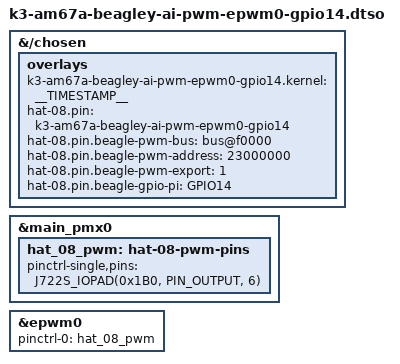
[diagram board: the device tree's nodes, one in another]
// SPDX-License-Identifier: GPL-2.0-only OR MIT
/*
 * DT Overlay for GPIO14 epwm0 connections within the expansion header.
 *
 * Copyright (C) 2023 Texas Instruments Incorporated - https://www.ti.com/
 *
 */

/dts-v1/;
/plugin/;

#include <dt-bindings/gpio/gpio.h>
#include "k3-pinctrl.h"

/*
 * Helper to show loaded overlays under: /proc/device-tree/chosen/overlays/
*/
&{/chosen} {
	overlays {
		k3-am67a-beagley-ai-pwm-epwm0-gpio14.kernel = __TIMESTAMP__;
		hat-08.pin = "k3-am67a-beagley-ai-pwm-epwm0-gpio14";
		hat-08.pin.beagle-pwm-bus = "bus@f0000";
		hat-08.pin.beagle-pwm-address = "23000000";
		hat-08.pin.beagle-pwm-export = "1";
		hat-08.pin.beagle-gpio-pi = "GPIO14";
	};
};

&main_pmx0 {
	hat_08_pwm: hat-08-pwm-pins {
		pinctrl-single,pins = <
			J722S_IOPAD(0x1B0, PIN_OUTPUT, 6) /* (F24) MCASP0_ACLKR.EHRPWM0_B */
		>;
	};
};

&epwm0 {
	pinctrl-names = "default";
	pinctrl-0 = <&hat_08_pwm>;
	status = "okay";
};
